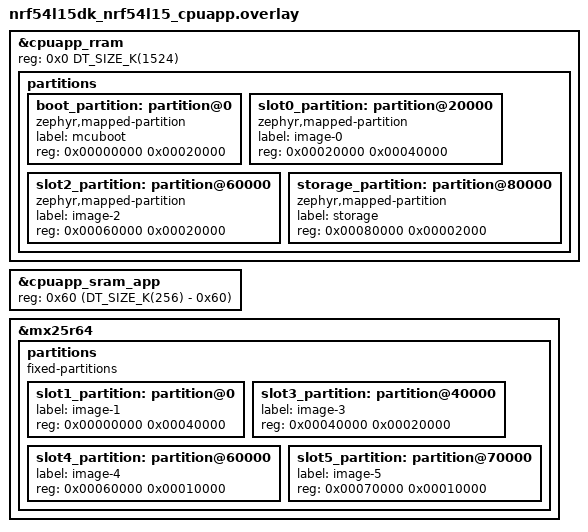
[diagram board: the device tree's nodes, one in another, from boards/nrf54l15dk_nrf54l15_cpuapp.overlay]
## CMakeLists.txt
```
#
# Copyright (c) 2025 Nordic Semiconductor
#
# SPDX-License-Identifier: LicenseRef-Nordic-5-Clause
#

cmake_minimum_required(VERSION 3.20.0)

find_package(Zephyr REQUIRED HINTS $ENV{ZEPHYR_BASE})
project(dfu_extra_test)

FILE(GLOB app_sources src/*.c)
target_sources(app PRIVATE ${app_sources})

# Link with MCUboot bootutil library (provides boot_image_load_header API)
target_link_libraries(app PRIVATE MCUBOOT_BOOTUTIL)
```

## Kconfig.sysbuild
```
#
# Copyright (c) 2025 Nordic Semiconductor ASA
#
# SPDX-License-Identifier: LicenseRef-Nordic-5-Clause
#

config BOOT_IMG_HASH_ALG_SHA512
	default n

source "share/sysbuild/Kconfig"
```

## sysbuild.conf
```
#
# Copyright (c) 2025 Nordic Semiconductor ASA
#
# SPDX-License-Identifier: LicenseRef-Nordic-5-Clause
#

SB_CONFIG_BOOTLOADER_MCUBOOT=y
SB_CONFIG_MCUBOOT_EXTRA_IMAGES=2
SB_CONFIG_MCUBOOT_UPDATEABLE_IMAGES=3
SB_CONFIG_DFU_MULTI_IMAGE_PACKAGE_BUILD=y
SB_CONFIG_DFU_MULTI_IMAGE_PACKAGE_APP=y
SB_CONFIG_PARTITION_MANAGER=y
```

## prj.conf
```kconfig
#
# Copyright (c) 2025 Nordic Semiconductor ASA
#
# SPDX-License-Identifier: LicenseRef-Nordic-5-Clause
#

CONFIG_FLASH=y
CONFIG_FLASH_MAP=y
CONFIG_STREAM_FLASH=y
CONFIG_IMG_MANAGER=y
CONFIG_MCUBOOT_IMG_MANAGER=y
CONFIG_BUILD_OUTPUT_META=y

CONFIG_SPI=y
CONFIG_SPI_NOR=y
CONFIG_SPI_NOR_SFDP_DEVICETREE=y
CONFIG_SPI_NOR_FLASH_LAYOUT_PAGE_SIZE=4096
```

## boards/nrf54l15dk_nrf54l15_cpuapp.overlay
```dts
/*
 * Copyright (c) 2025 Nordic Semiconductor ASA
 *
 * SPDX-License-Identifier: LicenseRef-Nordic-5-Clause
 */

/delete-node/ &boot_partition;
/delete-node/ &slot0_partition;
/delete-node/ &slot1_partition;
/delete-node/ &storage_partition;

/* restore full RRAM and SRAM space - by default some parts are dedicated to FLRP */
&cpuapp_rram {
	reg = <0x0 DT_SIZE_K(1524)>;

	partitions {
		boot_partition: partition@0 {
			compatible = "zephyr,mapped-partition";
			label = "mcuboot";
			reg = <0x00000000 0x00020000>;
		};

		slot0_partition: partition@20000 {
			compatible = "zephyr,mapped-partition";
			label = "image-0";
			reg = <0x00020000 0x00040000>;
		};

		slot2_partition: partition@60000 {
			compatible = "zephyr,mapped-partition";
			label = "image-2";
			reg = <0x00060000 0x00020000>;
		};

		storage_partition: partition@80000 {
			compatible = "zephyr,mapped-partition";
			label = "storage";
			reg = <0x00080000 0x00002000>;
		};
	};
};

&cpuapp_sram_app {
	reg = <0x60 (DT_SIZE_K(256) - 0x60)>;
};

&mx25r64 {
	status = "okay";

	partitions {
		compatible = "fixed-partitions";
		#address-cells = <1>;
		#size-cells = <1>;

		slot1_partition: partition@0 {
			label = "image-1";
			reg = <0x00000000 0x00040000>;
		};

		slot3_partition: partition@40000 {
			label = "image-3";
			reg = <0x00040000 0x00020000>;
		};

		slot4_partition: partition@60000 {
			label = "image-4";
			reg = <0x00060000 0x00010000>;
		};

		slot5_partition: partition@70000 {
			label = "image-5";
			reg = <0x00070000 0x00010000>;
		};
	};
};
```

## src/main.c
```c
#/*
 * Copyright (c) 2025 Nordic Semiconductor ASA
 *
 * SPDX-License-Identifier: LicenseRef-Nordic-5-Clause
 */

#include <zephyr/kernel.h>
#include <zephyr/storage/flash_map.h>
#include <bootutil/bootutil_public.h>
#include <bootutil/image.h>
#include <zephyr/storage/flash_map.h>

static void print_image_content(const char *name, uint32_t img_id,
				uint32_t img_address, uint32_t slot_size)
{
	uint8_t buffer[16];
	const struct flash_area *fa;
	struct image_header hdr;
	uint32_t img_size;
	int ret;

	printk("\n=== %s ===\n", name);
	printk("Slot: 0x%08x (%u bytes)\n", img_address, slot_size);

	ret = flash_area_open(img_id, &fa);
	if (ret != 0) {
		printk("Failed to open flash area\n");
		return;
	}

	ret = boot_image_load_header(fa, &hdr);
	if (ret != 0) {
		printk("No valid MCUboot image found\n");
		flash_area_close(fa);
		return;
	}

	if (hdr.ih_magic != IMAGE_MAGIC) {
		printk("Invalid image magic: 0x%08x\n", hdr.ih_magic);
		flash_area_close(fa);
		return;
	}

	img_size = hdr.ih_img_size;
	printk("Version: %u.%u.%u+%u\n",
	       hdr.ih_ver.iv_major, hdr.ih_ver.iv_minor,
	       hdr.ih_ver.iv_revision, hdr.ih_ver.iv_build_num);
	printk("Image size: %u bytes\n", img_size);
	printk("\nContent:\n");

	uint32_t bytes_read = 0;
	uint32_t offset = hdr.ih_hdr_size;

	while (bytes_read < img_size) {
		uint32_t chunk_size = (img_size - bytes_read) < sizeof(buffer)
				      ? (img_size - bytes_read) : sizeof(buffer);

		memset(buffer, 0, sizeof(buffer));
		ret = flash_area_read(fa, offset, buffer, chunk_size);
		if (ret != 0) {
			break;
		}

		printk("%04x: ", bytes_read);

		for (uint32_t i = 0; i < chunk_size; i++) {
			printk("%02x ", buffer[i]);
		}

		for (uint32_t i = chunk_size; i < 16; i++) {
			printk("   ");
		}

		printk(" |");
		for (uint32_t i = 0; i < chunk_size; i++) {
			char c = buffer[i];

			printk("%c", (c >= 32 && c <= 126) ? c : '.');
		}
		printk("|\n");

		bytes_read += chunk_size;
		offset += chunk_size;
	}

	flash_area_close(fa);
}

int main(void)
{
	printk("\n*** DFU Extra Images Test ***\n");

	print_image_content("Extra Image 1",
			    PARTITION_ID(slot2_partition),
			    PARTITION_ADDRESS(slot2_partition),
			    PARTITION_SIZE(slot2_partition));

	print_image_content("Extra Image 2",
			    PARTITION_ID(slot4_partition),
			    PARTITION_ADDRESS(slot4_partition),
			    PARTITION_SIZE(slot4_partition));

	printk("\nDone\n");
	return 0;
}
```
